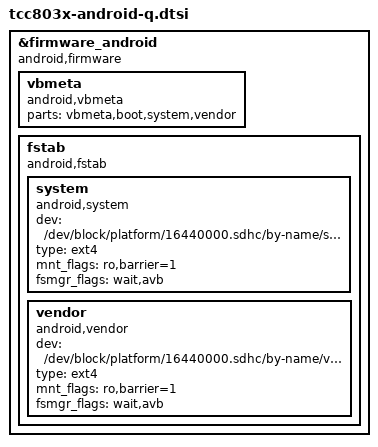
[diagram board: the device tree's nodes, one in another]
// SPDX-License-Identifier: (GPL-2.0+ OR MIT)
/*
 * Device tree for Telechips TCC803x Android platform
 *
 * Copyright (C) 2018 Telechips Inc.
 */

&firmware_android {
	compatible = "android,firmware";
	vbmeta {
		compatible = "android,vbmeta";
		parts = "vbmeta,boot,system,vendor";
	};
    /* if CONFIG_ANDROID_DYNAMIC_PARTITION is enabled delete fstab information */
	fstab {
		compatible = "android,fstab";
		system {
			compatible = "android,system";
			dev = "/dev/block/platform/16440000.sdhc/by-name/system";
			type = "ext4";
			mnt_flags = "ro,barrier=1";
#if !defined(CONFIG_ANDROID_AB_UPDATE)
			fsmgr_flags = "wait,avb";
#else
			fsmgr_flags = "wait,avb,slotselect";
#endif
		};
		vendor {
			compatible = "android,vendor";
			dev = "/dev/block/platform/16440000.sdhc/by-name/vendor";
			type = "ext4";
			mnt_flags = "ro,barrier=1";
#if !defined(CONFIG_ANDROID_AB_UPDATE)
			fsmgr_flags = "wait,avb";
#else
			fsmgr_flags = "wait,avb,slotselect";
#endif
		};
	};
};

